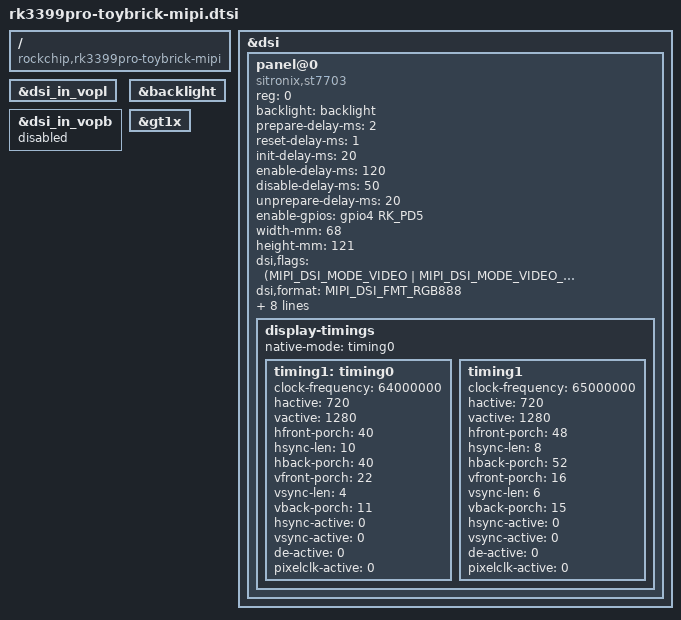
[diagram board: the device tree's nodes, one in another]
/*
 * Copyright (c) 2019 Fuzhou Rockchip Electronics Co., Ltd
 *
 * This file is dual-licensed: you can use it either under the terms
 * of the GPL or the X11 license, at your option. Note that this dual
 * licensing only applies to this file, and not this project as a
 * whole.
 *
 *  a) This file is free software; you can redistribute it and/or
 *     modify it under the terms of the GNU General Public License as
 *     published by the Free Software Foundation; either version 2 of the
 *     License, or (at your option) any later version.
 *
 *     This file is distributed in the hope that it will be useful,
 *     but WITHOUT ANY WARRANTY; without even the implied warranty of
 *     MERCHANTABILITY or FITNESS FOR A PARTICULAR PURPOSE.  See the
 *     GNU General Public License for more details.
 *
 * Or, alternatively,
 *
 *  b) Permission is hereby granted, free of charge, to any person
 *     obtaining a copy of this software and associated documentation
 *     files (the "Software"), to deal in the Software without
 *     restriction, including without limitation the rights to use,
 *     copy, modify, merge, publish, distribute, sublicense, and/or
 *     sell copies of the Software, and to permit persons to whom the
 *     Software is furnished to do so, subject to the following
 *     conditions:
 *
 *     The above copyright notice and this permission notice shall be
 *     included in all copies or substantial portions of the Software.
 *
 *     THE SOFTWARE IS PROVIDED "AS IS", WITHOUT WARRANTY OF ANY KIND,
 *     EXPRESS OR IMPLIED, INCLUDING BUT NOT LIMITED TO THE WARRANTIES
 *     OF MERCHANTABILITY, FITNESS FOR A PARTICULAR PURPOSE AND
 *     NONINFRINGEMENT. IN NO EVENT SHALL THE AUTHORS OR COPYRIGHT
 *     HOLDERS BE LIABLE FOR ANY CLAIM, DAMAGES OR OTHER LIABILITY,
 *     WHETHER IN AN ACTION OF CONTRACT, TORT OR OTHERWISE, ARISING
 *     FROM, OUT OF OR IN CONNECTION WITH THE SOFTWARE OR THE USE OR
 *     OTHER DEALINGS IN THE SOFTWARE.
 */

/ {
	compatible = "rockchip,rk3399pro-toybrick-mipi", "rockchip,rk3399pro";
};

&dsi {
	status = "okay";
	panel@0 {
		compatible = "sitronix,st7703", "simple-panel-dsi";
		status = "okay";
		reg = <0>;
		/*power-supply = <&vcc3v3_lcd>;*/
		backlight = <&backlight>;
		prepare-delay-ms = <2>;
		reset-delay-ms = <1>;
		init-delay-ms = <20>;
		enable-delay-ms = <120>;
		disable-delay-ms = <50>;
		unprepare-delay-ms = <20>;
		enable-gpios = <&gpio4 RK_PD5 GPIO_ACTIVE_HIGH>;
		width-mm = <68>;
		height-mm = <121>;

		dsi,flags = <(MIPI_DSI_MODE_VIDEO | MIPI_DSI_MODE_VIDEO_BURST |
				MIPI_DSI_MODE_LPM | MIPI_DSI_MODE_EOT_PACKET)>;
		dsi,format = <MIPI_DSI_FMT_RGB888>;
		dsi,lanes = <4>;

                /* It's used for distinguish the two mipi panel.
                   the 0xda means the panel id register.
                   the 0x38 means the value of panel id.
                   Using the panel-init-sequence-0 and timing0 if the the panel id register return 0x38.
                   Otherwise using the panel-init-sequence-1 and timing1.
                */
		panel-read-id = [
			39 00 02 da 38
		];
		panel-init-sequence-0 = [
			05 fa 01 11
			39 00 04 b9 f1 12 83
			39 00 1c ba 33 81 05 f9 0e 0e 00 00 00
				00 00 00 00 00 44 25 00 91 0a
				00 00 02 4f 01 00 00 37
			15 00 02 b8 25
			39 00 04 bf 02 11 00
			39 00 0b b3 0c 10 0a 50 03 ff 00 00 00
				00
			39 00 0a c0 73 73 50 50 00 00 08 70 00
			15 00 02 bc 46
			15 00 02 cc 0b
			15 00 02 b4 80
			39 00 04 b2 c8 12 30
			39 00 0f e3 07 07 0b 0b 03 0b 00 00 00
					00 ff 00 c0 10
			39 00 0d c1 53 00 1e 1e 77 e1 cc dd 67
				77 33 33
			39 00 07 c6 00 00 ff ff 01 ff
			39 00 03 b5 09 09
			39 00 03 b6 87 95
			39 00 40 e9 c2 10 05 05 10 05 a0 12 31
				23 3f 81 0a a0 37 18 00 80 01
				00 00 00 00 80 01 00 00 00 48
				f8 86 42 08 88 88 80 88 88 88
				58 f8 87 53 18 88 88 81 88 88
				88 00 00 00 01 00 00 00 00 00
				00 00 00 00
			39 00 3e ea 00 1a 00 00 00 00 02 00 00
				00 00 00 1f 88 81 35 78 88 88
				85 88 88 88 0f 88 80 24 68 88
				88 84 88 88 88 23 10 00 00 1c
				00 00 00 00 00 00 00 00 00 00
				00 00 00 00 00 30 05 a0 00 00
				00 00
			39 00 23 e0 00 06 08 2a 31 3f 38 36 07
				0c 0d 11 13 12 13 11 18 00 06
				08 2a 31 3f 38 36 07 0c 0d 11
				13 12 13 11 18
			05 32 01 29
		];
		panel-init-sequence-1 = [
			39 00 04 ff 98 81 03
			39 00 02 01 00
			39 00 02 02 00
			39 00 02 03 53
			39 00 02 04 53
			39 00 02 05 13
			39 00 02 06 04
			39 00 02 07 02
			39 00 02 08 02
			39 00 02 09 00
			39 00 02 0a 00
			39 00 02 0b 00
			39 00 02 0c 00
			39 00 02 0d 00
			39 00 02 0e 00
			39 00 02 0f 00
			39 00 02 10 00
			39 00 02 11 00
			39 00 02 12 00
			39 00 02 13 00
			39 00 02 14 00
			39 00 02 15 08
			39 00 02 16 10
			39 00 02 17 00
			39 00 02 18 08
			39 00 02 19 00
			39 00 02 1a 00
			39 00 02 1b 00
			39 00 02 1c 00
			39 00 02 1d 00
			39 00 02 1e c0
			39 00 02 1f 80
			39 00 02 20 02
			39 00 02 21 09
			39 00 02 22 00
			39 00 02 23 00
			39 00 02 24 00
			39 00 02 25 00
			39 00 02 26 00
			39 00 02 27 00
			39 00 02 28 55
			39 00 02 29 03
			39 00 02 2a 00
			39 00 02 2b 00
			39 00 02 2c 00
			39 00 02 2d 00
			39 00 02 2e 00
			39 00 02 2f 00
			39 00 02 30 00
			39 00 02 31 00
			39 00 02 32 00
			39 00 02 33 00
			39 00 02 34 04
			39 00 02 35 05
			39 00 02 36 05
			39 00 02 37 00
			39 00 02 38 3c
			39 00 02 39 35
			39 00 02 3a 00
			39 00 02 3b 40
			39 00 02 3c 00
			39 00 02 3d 00
			39 00 02 3e 00
			39 00 02 3f 00
			39 00 02 40 00
			39 00 02 41 88
			39 00 02 42 00
			39 00 02 43 00
			39 00 02 44 1f

			39 00 02 50 01
			39 00 02 51 23
			39 00 02 52 45
			39 00 02 53 67
			39 00 02 54 89
			39 00 02 55 ab
			39 00 02 56 01
			39 00 02 57 23
			39 00 02 58 45
			39 00 02 59 67
			39 00 02 5a 89
			39 00 02 5b ab
			39 00 02 5c cd
			39 00 02 5d ef
			39 00 02 5e 03
			39 00 02 5f 14

			39 00 02 60 15
			39 00 02 61 0c
			39 00 02 62 0d
			39 00 02 63 0e
			39 00 02 64 0f
			39 00 02 65 10
			39 00 02 66 11
			39 00 02 67 08
			39 00 02 68 02
			39 00 02 69 0a
			39 00 02 6a 02
			39 00 02 6b 02
			39 00 02 6c 02
			39 00 02 6d 02
			39 00 02 6e 02
			39 00 02 6f 02

			39 00 02 70 02
			39 00 02 71 02
			39 00 02 72 06
			39 00 02 73 02
			39 00 02 74 02
			39 00 02 75 14
			39 00 02 76 15
			39 00 02 77 0f
			39 00 02 78 0e
			39 00 02 79 0d
			39 00 02 7a 0c
			39 00 02 7b 11
			39 00 02 7c 10
			39 00 02 7d 06
			39 00 02 7e 02
			39 00 02 7f 0a

			39 00 02 80 02
			39 00 02 81 02
			39 00 02 82 02
			39 00 02 83 02
			39 00 02 84 02
			39 00 02 85 02
			39 00 02 86 02
			39 00 02 87 02
			39 00 02 88 08
			39 00 02 89 02
			39 00 02 8a 02

			39 00 04 ff 98 81 04
			39 00 02 00 80
			39 00 02 70 00
			39 00 02 71 00
			39 00 02 66 fe
			39 00 02 82 15
			39 00 02 84 15
			39 00 02 85 15
			39 00 02 3a 24
			39 00 02 32 ac
			39 00 02 8c 80
			39 00 02 3c f5
			39 00 02 88 33

			39 00 04 ff 98 81 01
			39 00 02 22 0a
			39 00 02 31 00
			39 00 02 53 78
			39 00 02 55 7b
			39 00 02 60 20
			39 00 02 61 00
			39 00 02 62 0d
			39 00 02 63 00

			39 00 02 a0 00
			39 00 02 a1 10
			39 00 02 a2 1c
			39 00 02 a3 13
			39 00 02 a4 15
			39 00 02 a5 26
			39 00 02 a6 1a
			39 00 02 a7 1d
			39 00 02 a8 67
			39 00 02 a9 1c
			39 00 02 aa 29
			39 00 02 ab 58
			39 00 02 ac 26
			39 00 02 ad 28
			39 00 02 ae 5c
			39 00 02 af 30
			39 00 02 b0 31
			39 00 02 b1 32
			39 00 02 b2 00

			39 00 02 c0 00
			39 00 02 c1 10
			39 00 02 c2 1c
			39 00 02 c3 13
			39 00 02 c4 15
			39 00 02 c5 26
			39 00 02 c6 1a
			39 00 02 c7 1d
			39 00 02 c8 67
			39 00 02 c9 1c
			39 00 02 ca 29
			39 00 02 cb 5b
			39 00 02 cc 26
			39 00 02 cd 28
			39 00 02 ce 5c
			39 00 02 cf 30
			39 00 02 d0 31
			39 00 02 d1 2e
			39 00 02 d2 32
			39 00 02 d3 00

			39 00 04 ff 98 81 00
			05 fa 01 11
			05 14 01 29
		];


		panel-exit-sequence = [
			05 00 01 28
			05 00 01 10
		];

		display-timings {
			native-mode = <&timing0>;

			timing1: timing0 {
				clock-frequency = <64000000>;
				hactive = <720>;
				vactive = <1280>;
				hfront-porch = <40>;
				hsync-len = <10>;
				hback-porch = <40>;
				vfront-porch = <22>;
				vsync-len = <4>;
				vback-porch = <11>;
				hsync-active = <0>;
				vsync-active = <0>;
				de-active = <0>;
				pixelclk-active = <0>;
			};
			timing1: timing1 {
				clock-frequency = <65000000>;
				hactive = <720>;
				vactive = <1280>;
				hfront-porch = <48>;
				hsync-len = <8>;
				hback-porch = <52>;
				vfront-porch = <16>;
				vsync-len = <6>;
				vback-porch = <15>;
				hsync-active = <0>;
				vsync-active = <0>;
				de-active = <0>;
				pixelclk-active = <0>;
			};

		};
	};
};

&dsi_in_vopl {
	status = "okay";
};

&dsi_in_vopb {
	status = "disabled";
};

&backlight {
        status = "okay";
};

&gt1x {
        status = "okay";
};
